AUTOSAR XML (schema 4-0-3)
package /AppSwComponent_Dem/SwComponentType
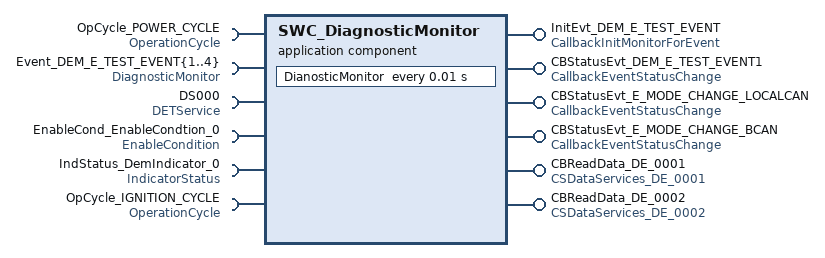
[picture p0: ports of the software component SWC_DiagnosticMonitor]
  application sw component type SWC_DiagnosticMonitor
    provide port InitEvt_DEM_E_TEST_EVENT: server-com-spec{operation=InitMonitorForEvent, queue-length=1}, provided-interface=CallbackInitMonitorForEvent
    5 x require port:
      OpCycle_POWER_CYCLE: client-com-spec=SetOperationCycleState, required-interface=OperationCycle
      Event_DEM_E_TEST_EVENT{1..4}: client-com-spec=SetEventStatus, required-interface=DiagnosticMonitor
    provide port CBStatusEvt_DEM_E_TEST_EVENT1: server-com-spec{operation=EventStatusChanged, queue-length=1}, provided-interface=CallbackEventStatusChange
    require port DS000: client-com-spec=ReportError, required-interface=DETService
    4 x provide port:
      CBStatusEvt_E_MODE_CHANGE_LOCALCAN: server-com-spec{operation=EventStatusChanged, queue-length=1}, provided-interface=CallbackEventStatusChange
      CBStatusEvt_E_MODE_CHANGE_BCAN: server-com-spec{operation=EventStatusChanged, queue-length=1}, provided-interface=CallbackEventStatusChange
      CBReadData_DE_0001: server-com-spec{operation=ReadData, queue-length=1}, provided-interface=CSDataServices_DE_0001
      CBReadData_DE_0002: server-com-spec{operation=ReadData, queue-length=1}, provided-interface=CSDataServices_DE_0002
    require port EnableCond_EnableCondtion_0: client-com-spec=SetEnableCondition, required-interface=EnableCondition
    require port IndStatus_DemIndicator_0: client-com-spec=GetIndicatorStatus, required-interface=IndicatorStatus
    require port OpCycle_IGNITION_CYCLE: client-com-spec=SetOperationCycleState, required-interface=OperationCycle
    behavior InternalBehaviors_DiagnosticMonitor: included-data-type-set=data-type=Dem_OperationCycleStateType
      timing event TimingEvent_DiagnosticMonitor: start-on-event=DianosticMonitor, period=0.01
      6 x operation invoked event:
        OIE_InitMonitorForEvent: start-on-event=InitMonitorForEvent_DEM_E_TEST, operation=InitEvt_DEM_E_TEST_EVENT.InitMonitorForEvent
        OIE_CBStatusEvt_DEM_E_TEST_EVENT: start-on-event=CBStatusEvt_DEM_E_TEST_EVENT1, operation=CBStatusEvt_DEM_E_TEST_EVENT1.EventStatusChanged
        OIE_CBStatusEvt_E_MODE_CHANGE_LOCALCAN_CBStatusEvt_E_MODE_CHANGE_LOCALCAN_EventStatusChanged: start-on-event=CBStatusEvt_E_MODE_CHANGE_LOCALCAN, operation=CBStatusEvt_E_MODE_CHANGE_LOCALCAN.EventStatusChanged
        OIE_CBStatusEvt_E_MODE_CHANGE_BCAN_CBStatusEvt_E_MODE_CHANGE_BCAN_EventStatusChanged: start-on-event=CBStatusEvt_E_MODE_CHANGE_BCAN, operation=CBStatusEvt_E_MODE_CHANGE_BCAN.EventStatusChanged
        OIE_CBReadData_DE_0001: start-on-event=CBReadData_DE_0001, operation=CBReadData_DE_0001.ReadData
        OIE_CBReadData_DE_0002: start-on-event=CBReadData_DE_0002, operation=CBReadData_DE_0002.ReadData
      7 x runnable, all with can-be-invoked-concurrently=true:
        DianosticMonitor: symbol=DiagnosticMonitor
          9 x sync call:
            SSCP_SetOperationCycleState: operation=OpCycle_POWER_CYCLE.SetOperationCycleState
            DEM_E_TEST_EVENT{1..4}_SetEventStatus: operation=Event_DEM_E_TEST_EVENT{1..4}.SetEventStatus
            Det_ReportError_DS000: operation=DS000.ReportError
            EnableCond_EnableCondition_0: operation=EnableCond_EnableCondtion_0.SetEnableCondition
            IndStatus_DemIndicator_0: operation=IndStatus_DemIndicator_0.GetIndicatorStatus
            SSCP_DianosticMonitor_OpCycle_IGNITION_CYCLE_SetOperationCycleState: operation=OpCycle_IGNITION_CYCLE.SetOperationCycleState
        InitMonitorForEvent_DEM_E_TEST
        CBStatusEvt_DEM_E_TEST_EVENT1
        CBStatusEvt_E_MODE_CHANGE_LOCALCAN
        CBStatusEvt_E_MODE_CHANGE_BCAN
        CBReadData_DE_0001
        CBReadData_DE_0002
  swc implementation SWC_DiagnosticMonitor_Implementation: behavior=InternalBehaviors_DiagnosticMonitor
    code-descriptors:
      code Default
